VERSION ""

NS_ :

BS_:

BU_: front_ecu central_ecu rear_ecu

BO_ 513 tachometer: 2 rear_ecu
 SG_ rpm : 0|16@1+ (1,0) [0|65535] "rpm" Vector__XXX

BO_ 514 speedometer: 2 rear_ecu
 SG_ kph : 0|16@1+ (1,0) [0|65535] "kph" Vector__XXX

BO_ 515 left_linpot: 2 rear_ecu
 SG_ kph : 0|16@1+ (1,0) [0|65535] "cm" Vector__XXX

BO_ 515 right_linpot: 2 rear_ecu
 SG_ kph : 0|16@1+ (1,0) [0|65535] "cm" Vector__XXX

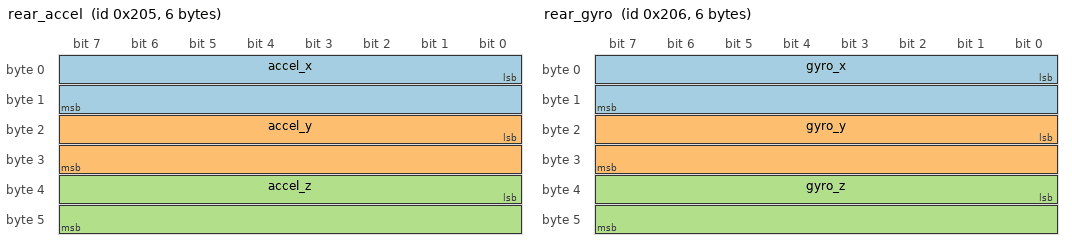
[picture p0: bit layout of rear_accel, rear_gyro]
BO_ 517 rear_accel: 6 rear_ecu
  SG_ accel_x : 0|16@1- (0.000244140625,0) [-8|8] "g" Vector__XXX
  SG_ accel_y : 16|16@1- (0.000244140625,0) [-8|8] "g" Vector__XXX
  SG_ accel_z : 32|16@1- (0.000244140625,0) [-8|8] "g" Vector__XXX

BO_ 518 rear_gyro: 6 rear_ecu
  SG_ gyro_x : 0|16@1- (0.061,0) [-2000|2000] "dps" Vector__XXX
  SG_ gyro_y : 16|16@1- (0.061,0) [-2000|2000] "dps" Vector__XXX
  SG_ gyro_z : 32|16@1- (0.061,0) [-2000|2000] "dps" Vector__XXX

BO_ 769 steering_angle: 2 front_ecu
 SG_ rpm : 0|16@1+ (1,0) [0|65535] "deg" Vector__XXX

BA_DEF_ BO_  "VFrameFormat" ENUM  "StandardCAN","ExtendedCAN","reserved","J1939PG";
BA_DEF_  "DatabaseVersion" STRING ;
BA_DEF_  "BusType" STRING ;
BA_DEF_  "ProtocolType" STRING ;
BA_DEF_  "DatabaseCompiler" STRING ;
BA_DEF_DEF_  "VFrameFormat" "StandardCAN";
BA_DEF_DEF_  "DatabaseVersion" "";
BA_DEF_DEF_  "BusType" "";
BA_DEF_DEF_  "ProtocolType" "";
BA_DEF_DEF_  "DatabaseCompiler" "";
BA_ "BusType" "CAN";
BA_ "DatabaseCompiler" "UBC BAJA";
BA_ "DatabaseVersion" "1.0.0";
